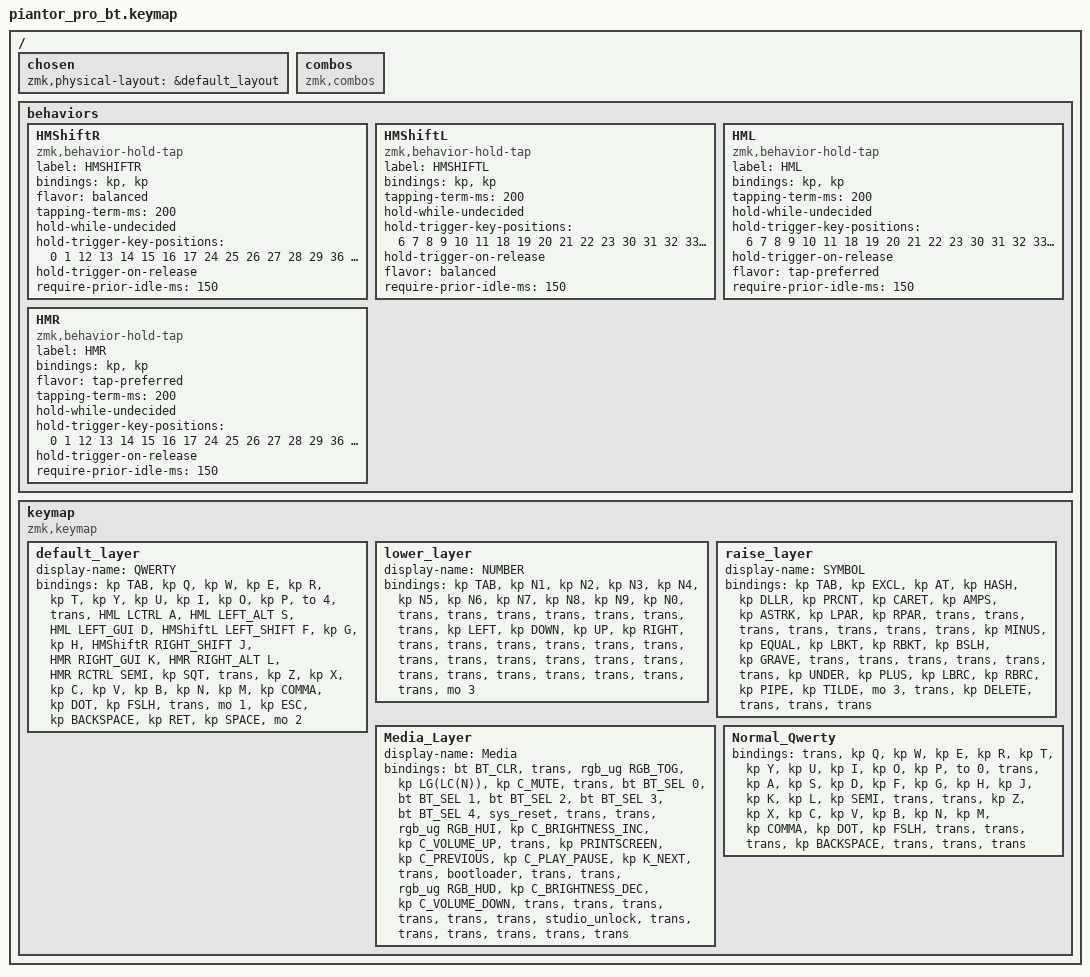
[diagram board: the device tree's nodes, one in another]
/*
 * Copyright (c) 2020 The ZMK Contributors
 *
 * SPDX-License-Identifier: MIT
 */

#include <behaviors.dtsi>
#include <dt-bindings/zmk/bt.h>
#include <dt-bindings/zmk/keys.h>
#include <dt-bindings/zmk/rgb.h>

/ {
    chosen { zmk,physical-layout = &default_layout; };
};

/ {
    combos { compatible = "zmk,combos"; };

    behaviors {
        HMShiftR: HMShiftR {
            compatible = "zmk,behavior-hold-tap";
            label = "HMSHIFTR";
            bindings = <&kp>, <&kp>;

            #binding-cells = <2>;
            flavor = "balanced";
            tapping-term-ms = <200>;
            hold-while-undecided;
            hold-trigger-key-positions = <0 1 12 13 14 15 16 17 24 25 26 27 28 29 36 37 38 2 3 4 5>;
            hold-trigger-on-release;
            require-prior-idle-ms = <150>;
        };

        HMShiftL: HMShiftL {
            compatible = "zmk,behavior-hold-tap";
            label = "HMSHIFTL";
            bindings = <&kp>, <&kp>;

            #binding-cells = <2>;
            tapping-term-ms = <200>;
            hold-while-undecided;
            hold-trigger-key-positions = <6 7 8 9 10 11 18 19 20 21 22 23 30 31 32 33 34 35 40 41 39>;
            hold-trigger-on-release;
            flavor = "balanced";
            require-prior-idle-ms = <150>;
        };

        HML: HML {
            compatible = "zmk,behavior-hold-tap";
            label = "HML";
            bindings = <&kp>, <&kp>;

            #binding-cells = <2>;
            tapping-term-ms = <200>;
            hold-while-undecided;
            hold-trigger-key-positions = <6 7 8 9 10 11 18 19 20 21 22 23 30 31 32 33 34 35 40 41 39>;
            hold-trigger-on-release;
            flavor = "tap-preferred";
            require-prior-idle-ms = <150>;
        };

        HMR: HMR {
            compatible = "zmk,behavior-hold-tap";
            label = "HMR";
            bindings = <&kp>, <&kp>;

            #binding-cells = <2>;
            flavor = "tap-preferred";
            tapping-term-ms = <200>;
            hold-while-undecided;
            hold-trigger-key-positions = <0 1 12 13 14 15 16 17 24 25 26 27 28 29 36 37 38 2 3 4 5>;
            hold-trigger-on-release;
            require-prior-idle-ms = <150>;
        };
    };

    keymap {
        compatible = "zmk,keymap";

        default_layer {
            display-name = "QWERTY";

            // --------------------------------------------------------------------------------
            // |  TAB |  Q  |  W  |  E  |  R  |  T  |  Y  |  U   |  I  |  O  |  P  | BSPC |
            // | CTRL |  A  |  S  |  D  |  F  |  G  |  H  |  J   |  K  |  L  |  ;  |  '   |
            // | SHFT |  Z  |  X  |  C  |  V  |  B  |  N  |  M   |  ,  |  .  |  /  | ESC  |
            //                    | GUI | LWR | SPC | ENT | RSE  | ALT |

            bindings = <
&kp TAB  &kp Q  &kp W  &kp E  &kp R  &kp T  &kp Y  &kp U  &kp I  &kp O  &kp P  &to 4  &trans  &HML LCTRL A  &HML LEFT_ALT S  &HML LEFT_GUI D  &HMShiftL LEFT_SHIFT F  &kp G  &kp H  &HMShiftR RIGHT_SHIFT J  &HMR RIGHT_GUI K  &HMR RIGHT_ALT L  &HMR RCTRL SEMI  &kp SQT  &trans  &kp Z  &kp X  &kp C  &kp V  &kp B  &kp N  &kp M  &kp COMMA  &kp DOT  &kp FSLH  &trans  &mo 1  &kp ESC  &kp BACKSPACE  &kp RET  &kp SPACE  &mo 2
            >;
        };

        lower_layer {
            display-name = "NUMBER";

            // -----------------------------------------------------------------------------------------
            // |  TAB |  1  |  2  |  3  |  4  |  5    |  6  |  7  |  8  |  9  |  0  | BSPC |
            // | CTRL | BT1 | BT2 | BT3 | BT4 | BT5   | LFT | DWN |  UP | RGT |     |      |
            // | SHFT | BTCR| RGB | RST | BOOT| Unlock|     |     |     |     |     |      |
            //                    | GUI |     | SPC   | ENT |     | ALT |

            bindings = <
&kp TAB  &kp N1  &kp N2  &kp N3  &kp N4  &kp N5  &kp N6  &kp N7  &kp N8  &kp N9  &kp N0  &trans  &trans  &trans  &trans  &trans  &trans  &trans  &kp LEFT  &kp DOWN  &kp UP  &kp RIGHT  &trans  &trans  &trans  &trans  &trans  &trans  &trans  &trans  &trans  &trans  &trans  &trans  &trans  &trans  &trans  &trans  &trans  &trans  &trans  &mo 3
            >;
        };

        raise_layer {
            display-name = "SYMBOL";

            // -----------------------------------------------------------------------------------------
            // |  TAB |  !  |  @  |  #  |  $  |  %  |  ^  |  &  |  *  |  (  |  )  | BSPC |
            // | CTRL | HUD | HUI |     |     |     |  -  |  =  |  [  |  ]  |  \  |  `   |
            // | SHFT |     |     |     |     |     |  _  |  +  |  {  |  }  | "|" |  ~   |
            //                    | GUI |     | SPC | ENT |     | ALT |

            bindings = <
&kp TAB  &kp EXCL  &kp AT  &kp HASH  &kp DLLR  &kp PRCNT  &kp CARET  &kp AMPS  &kp ASTRK  &kp LPAR  &kp RPAR  &trans  &trans  &trans  &trans  &trans  &trans  &trans  &kp MINUS  &kp EQUAL  &kp LBKT  &kp RBKT  &kp BSLH  &kp GRAVE  &trans  &trans  &trans  &trans  &trans  &trans  &kp UNDER  &kp PLUS  &kp LBRC  &kp RBRC  &kp PIPE  &kp TILDE  &mo 3  &trans  &kp DELETE  &trans  &trans  &trans
            >;
        };

        Media_Layer {
            display-name = "Media";
            bindings = <
&bt BT_CLR  &trans  &rgb_ug RGB_TOG  &kp LG(LC(N))  &kp C_MUTE  &trans  &bt BT_SEL 0  &bt BT_SEL 1  &bt BT_SEL 2  &bt BT_SEL 3  &bt BT_SEL 4  &sys_reset  &trans  &trans  &rgb_ug RGB_HUI  &kp C_BRIGHTNESS_INC  &kp C_VOLUME_UP  &trans  &kp PRINTSCREEN  &kp C_PREVIOUS  &kp C_PLAY_PAUSE  &kp K_NEXT  &trans  &bootloader  &trans  &trans  &rgb_ug RGB_HUD  &kp C_BRIGHTNESS_DEC  &kp C_VOLUME_DOWN  &trans  &trans  &trans  &trans  &trans  &trans  &studio_unlock  &trans  &trans  &trans  &trans  &trans  &trans
            >;
        };

        Normal_Qwerty {
            bindings = <
&trans  &kp Q  &kp W  &kp E  &kp R  &kp T  &kp Y  &kp U  &kp I  &kp O  &kp P  &to 0  &trans  &kp A  &kp S  &kp D  &kp F  &kp G  &kp H  &kp J  &kp K  &kp L  &kp SEMI  &trans  &trans  &kp Z  &kp X  &kp C  &kp V  &kp B  &kp N  &kp M  &kp COMMA  &kp DOT  &kp FSLH  &trans  &trans  &trans  &kp BACKSPACE  &trans  &trans  &trans
            >;
        };
    };
};
